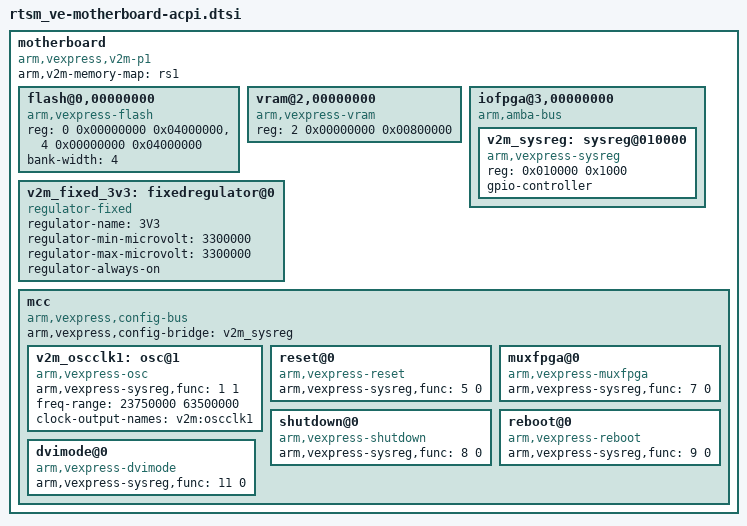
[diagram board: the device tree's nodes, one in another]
/*
 * Copyright (c) 2013, ARM Limited. All rights reserved.
 *
 * Redistribution and use in source and binary forms, with or without
 * modification, are permitted provided that the following conditions are met:
 *
 * Redistributions of source code must retain the above copyright notice, this
 * list of conditions and the following disclaimer.
 *
 * Redistributions in binary form must reproduce the above copyright notice,
 * this list of conditions and the following disclaimer in the documentation
 * and/or other materials provided with the distribution.
 *
 * Neither the name of ARM nor the names of its contributors may be used
 * to endorse or promote products derived from this software without specific
 * prior written permission.
 *
 * THIS SOFTWARE IS PROVIDED BY THE COPYRIGHT HOLDERS AND CONTRIBUTORS "AS IS"
 * AND ANY EXPRESS OR IMPLIED WARRANTIES, INCLUDING, BUT NOT LIMITED TO, THE
 * IMPLIED WARRANTIES OF MERCHANTABILITY AND FITNESS FOR A PARTICULAR PURPOSE
 * ARE DISCLAIMED. IN NO EVENT SHALL THE COPYRIGHT HOLDER OR CONTRIBUTORS BE
 * LIABLE FOR ANY DIRECT, INDIRECT, INCIDENTAL, SPECIAL, EXEMPLARY, OR
 * CONSEQUENTIAL DAMAGES (INCLUDING, BUT NOT LIMITED TO, PROCUREMENT OF
 * SUBSTITUTE GOODS OR SERVICES; LOSS OF USE, DATA, OR PROFITS; OR BUSINESS
 * INTERRUPTION) HOWEVER CAUSED AND ON ANY THEORY OF LIABILITY, WHETHER IN
 * CONTRACT, STRICT LIABILITY, OR TORT (INCLUDING NEGLIGENCE OR OTHERWISE)
 * ARISING IN ANY WAY OUT OF THE USE OF THIS SOFTWARE, EVEN IF ADVISED OF THE
 * POSSIBILITY OF SUCH DAMAGE.
 */

	motherboard {
		arm,v2m-memory-map = "rs1";
		compatible = "arm,vexpress,v2m-p1", "simple-bus";
		#address-cells = <2>; /* SMB chipselect number and offset */
		#size-cells = <1>;
		#interrupt-cells = <1>;
		ranges;

		flash@0,00000000 {
			compatible = "arm,vexpress-flash", "cfi-flash";
			reg = <0 0x00000000 0x04000000>,
			      <4 0x00000000 0x04000000>;
			bank-width = <4>;
		};

		vram@2,00000000 {
			compatible = "arm,vexpress-vram";
			reg = <2 0x00000000 0x00800000>;
		};

		iofpga@3,00000000 {
			compatible = "arm,amba-bus", "simple-bus";
			#address-cells = <1>;
			#size-cells = <1>;
			ranges = <0 3 0 0x200000>;

			v2m_sysreg: sysreg@010000 {
				compatible = "arm,vexpress-sysreg";
				reg = <0x010000 0x1000>;
				gpio-controller;
				#gpio-cells = <2>;
			};

		};

		v2m_fixed_3v3: fixedregulator@0 {
			compatible = "regulator-fixed";
			regulator-name = "3V3";
			regulator-min-microvolt = <3300000>;
			regulator-max-microvolt = <3300000>;
			regulator-always-on;
		};

		mcc {
			compatible = "arm,vexpress,config-bus", "simple-bus";
			arm,vexpress,config-bridge = <&v2m_sysreg>;

			v2m_oscclk1: osc@1 {
				/* CLCD clock */
				compatible = "arm,vexpress-osc";
				arm,vexpress-sysreg,func = <1 1>;
				freq-range = <23750000 63500000>;
				#clock-cells = <0>;
				clock-output-names = "v2m:oscclk1";
			};

			reset@0 {
				compatible = "arm,vexpress-reset";
				arm,vexpress-sysreg,func = <5 0>;
			};

			muxfpga@0 {
				compatible = "arm,vexpress-muxfpga";
				arm,vexpress-sysreg,func = <7 0>;
			};

			shutdown@0 {
				compatible = "arm,vexpress-shutdown";
				arm,vexpress-sysreg,func = <8 0>;
			};

			reboot@0 {
				compatible = "arm,vexpress-reboot";
				arm,vexpress-sysreg,func = <9 0>;
			};

			dvimode@0 {
				compatible = "arm,vexpress-dvimode";
				arm,vexpress-sysreg,func = <11 0>;
			};
		};
	};
